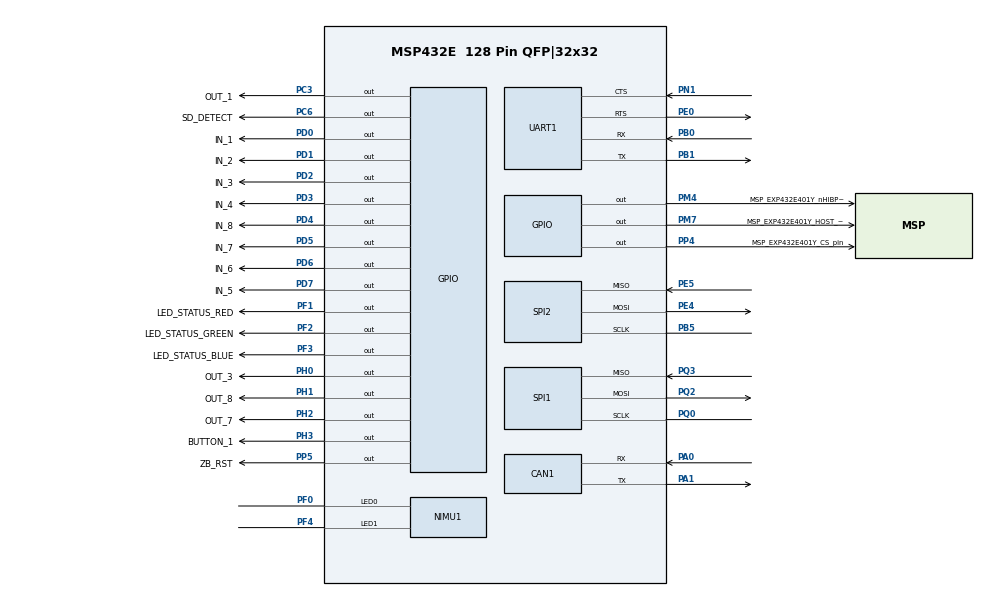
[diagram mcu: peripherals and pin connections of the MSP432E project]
/**
 * @cliArgs --device "MSP432E" --package "128 Pin QFP|32x32" --part "MSP432E401YTPDT" --product "simplelink_msp432e4_sdk@4.20.00.12"
 * @versions {"tool":"1.18.1+3343"}
 */

/**
 * Import the modules used in this configuration.
 */
const CAN     = scripting.addModule("/ti/drivers/CAN", {}, false);
const CAN1    = CAN.addInstance();
const GPIO    = scripting.addModule("/ti/drivers/GPIO", {}, false);
const GPIO1   = GPIO.addInstance();
const GPIO2   = GPIO.addInstance();
const GPIO3   = GPIO.addInstance();
const GPIO4   = GPIO.addInstance();
const GPIO5   = GPIO.addInstance();
const GPIO6   = GPIO.addInstance();
const GPIO7   = GPIO.addInstance();
const GPIO8   = GPIO.addInstance();
const GPIO9   = GPIO.addInstance();
const GPIO10  = GPIO.addInstance();
const GPIO11  = GPIO.addInstance();
const GPIO12  = GPIO.addInstance();
const GPIO13  = GPIO.addInstance();
const GPIO14  = GPIO.addInstance();
const GPIO15  = GPIO.addInstance();
const GPIO16  = GPIO.addInstance();
const GPIO17  = GPIO.addInstance();
const NVS     = scripting.addModule("/ti/drivers/NVS", {}, false);
const NVS1    = NVS.addInstance();
const NVS2    = NVS.addInstance();
const RTOS    = scripting.addModule("/ti/drivers/RTOS");
const SPI     = scripting.addModule("/ti/drivers/SPI", {}, false);
const SPI1    = SPI.addInstance();
const SPI2    = SPI.addInstance();
const Timer   = scripting.addModule("/ti/drivers/Timer", {}, false);
const Timer1  = Timer.addInstance();
const UART    = scripting.addModule("/ti/drivers/UART", {}, false);
const UART1   = UART.addInstance();
const Button  = scripting.addModule("/ti/drivers/apps/Button");
const Button1 = Button.addInstance();
const LED     = scripting.addModule("/ti/drivers/apps/LED");
const LED1    = LED.addInstance();
const LED2    = LED.addInstance();
const LED3    = LED.addInstance();
const General = scripting.addModule("/ti/ndk/General");
const NIMU    = scripting.addModule("/ti/ndk/NIMU", {}, false);
const NIMU1   = NIMU.addInstance();
const SlNet   = scripting.addModule("/ti/net/SlNet", {}, false);
const SlNet1  = SlNet.addInstance();

/**
 * Write custom configuration values to the imported modules.
 */
CAN1.$name             = "CONFIG_CAN0";
CAN1.can.$assign       = "CAN0";
CAN1.can.rxPin.$assign = "PA0";
CAN1.can.txPin.$assign = "PA1";

GPIO1.mode            = "Output";
GPIO1.$name           = "OUT_1";
GPIO1.gpioPin.$assign = "PC3";

GPIO2.mode            = "Output";
GPIO2.$name           = "OUT_3";
GPIO2.gpioPin.$assign = "PH0";

GPIO3.mode            = "Output";
GPIO3.$name           = "OUT_8";
GPIO3.gpioPin.$assign = "PH1";

GPIO4.mode            = "Output";
GPIO4.$name           = "OUT_7";
GPIO4.gpioPin.$assign = "PH2";

GPIO5.callbackFunction = "get_8io";
GPIO5.interruptTrigger = "Both Edges";
GPIO5.pull             = "Pull Up";
GPIO5.$name            = "IN_4";
GPIO5.gpioPin.$assign  = "PD3";

GPIO6.callbackFunction = "get_8io";
GPIO6.interruptTrigger = "Both Edges";
GPIO6.pull             = "Pull Up";
GPIO6.$name            = "IN_3";
GPIO6.gpioPin.$assign  = "PD2";

GPIO7.callbackFunction = "get_8io";
GPIO7.interruptTrigger = "Both Edges";
GPIO7.pull             = "Pull Up";
GPIO7.$name            = "IN_2";
GPIO7.gpioPin.$assign  = "PD1";

GPIO8.callbackFunction = "get_8io";
GPIO8.interruptTrigger = "Both Edges";
GPIO8.pull             = "Pull Up";
GPIO8.$name            = "IN_1";
GPIO8.gpioPin.$assign  = "PD0";

GPIO9.callbackFunction = "get_8io";
GPIO9.interruptTrigger = "Both Edges";
GPIO9.pull             = "Pull Up";
GPIO9.$name            = "IN_8";
GPIO9.gpioPin.$assign  = "PD4";

GPIO10.callbackFunction = "get_8io";
GPIO10.interruptTrigger = "Both Edges";
GPIO10.pull             = "Pull Up";
GPIO10.$name            = "IN_7";
GPIO10.gpioPin.$assign  = "PD5";

GPIO11.callbackFunction = "get_8io";
GPIO11.interruptTrigger = "Both Edges";
GPIO11.pull             = "Pull Up";
GPIO11.$name            = "IN_6";
GPIO11.gpioPin.$assign  = "PD6";

GPIO12.callbackFunction = "get_8io";
GPIO12.interruptTrigger = "Both Edges";
GPIO12.pull             = "Pull Up";
GPIO12.$name            = "IN_5";
GPIO12.gpioPin.$assign  = "PD7";

GPIO13.$name            = "SD_DETECT";
GPIO13.callbackFunction = "sd_pinevent";
GPIO13.interruptTrigger = "Both Edges";
GPIO13.gpioPin.$assign  = "PC6";

GPIO14.$name           = "ZB_RST";
GPIO14.gpioPin.$assign = "PP5";

GPIO15.$name            = "MSP_EXP432E401Y_HOST_IRQ";
GPIO15.pull             = "Pull Down";
GPIO15.interruptTrigger = "Rising Edge";
GPIO15.gpioPin.$assign  = "PM7";

GPIO16.$name           = "MSP_EXP432E401Y_nHIBPin";
GPIO16.mode            = "Output";
GPIO16.outputStrength  = "High";
GPIO16.gpioPin.$assign = "PM4";

GPIO17.$name              = "MSP_EXP432E401Y_CS_pin";
GPIO17.mode               = "Output";
GPIO17.outputStrength     = "High";
GPIO17.initialOutputState = "High";
GPIO17.gpioPin.$assign    = "PP4";

NVS1.$name                    = "CONFIG_NVS_0";
NVS1.internalFlash.$name      = "ti_drivers_nvs_NVSMSP432E40";
NVS1.internalFlash.regionType = "Pointer";
NVS1.internalFlash.regionBase = 0xFC000;

NVS2.nvsType                  = "External";
NVS2.$name                    = "EXTERNAL";
NVS2.externalFlash.$name      = "ti_drivers_nvs_NVSSPI25X0";
NVS2.externalFlash.regionSize = 0x200000;
NVS2.externalFlash.regionBase = 0x20040000;

RTOS.timer0.resource.$assign = "Timer0";

SPI2.$name               = "CONFIG_SPI_WIFI";
SPI2.spi.$assign         = "SSI1";
SPI2.spi.sclkPin.$assign = "PB5";
SPI2.spi.misoPin.$assign = "PE5";
SPI2.spi.mosiPin.$assign = "PE4";

Timer1.$name         = "CONFIG_TIMER_0";
Timer1.timerType     = "32 Bits";
Timer1.timer.$assign = "Timer1";

UART1.$name               = "ZNP_UART";
UART1.flowControl         = true;
UART1.uart.txPin.$assign  = "PB1";
UART1.uart.rxPin.$assign  = "PB0";
UART1.uart.ctsPin.$assign = "PN1";
UART1.uart.rtsPin.$assign = "PE0";

Button1.$name                   = "BUTTON_1";
Button1.gpioPin.$name           = "CONFIG_GPIO_2";
Button1.gpioPin.gpioPin.$assign = "PH3";

LED1.$name                   = "LED_STATUS_RED";
LED1.gpioPin.gpioPin.$assign = "PF1";

LED2.$name                   = "LED_STATUS_BLUE";
LED2.gpioPin.gpioPin.$assign = "PF3";

LED3.$name                   = "LED_STATUS_GREEN";
LED3.gpioPin.gpioPin.$assign = "PF2";

const NVSSPI25XDevice                          = scripting.addModule("/ti/drivers/nvs/NVSSPI25XDevice", {}, false);
const NVSSPI25XDevice1                         = NVSSPI25XDevice.addInstance({}, false);
NVS2.externalFlash.spiFlashDevice              = NVSSPI25XDevice1;
NVSSPI25XDevice1.$name                         = "CONFIG_NVS_SPI_";
NVSSPI25XDevice1.bitRate                       = 12000000;
NVSSPI25XDevice1.slaveSelectGpioInstance.$name = "CONFIG_GPIO_0";

NVSSPI25XDevice1.sharedSpiInstance = SPI1;
SPI1.$name                         = "CONFIG_SPI_FLASH";
SPI1.spi.$assign                   = "SSI3";
SPI1.spi.sclkPin.$assign           = "PQ0";
SPI1.spi.misoPin.$assign           = "PQ3";
SPI1.spi.mosiPin.$assign           = "PQ2";

General.networkIPAddrHook       = "on_ip_change";
General.hostname                = "swaway-rt";
General.enableExtDNS            = true;
General.externDNSServIPAddr     = "9.9.9.9";
General.maxNumSocks             = 20;
General.ndkThreadStkSize        = 4096;
General.netTaskSchedulerTaskPri = "NC_PRIORITY_HIGH";
General.numPBMFrames            = 20;
General.tcpTxBufSize            = 4096;

NIMU1.$name                     = "CONFIG_NIMU_0";
NIMU1.dhcpcServReportFxn        = "on_ip_change";
NIMU1.staticIPAddr              = "192.168.20.98";
NIMU1.gatewayIpAddr             = "192.168.20.1";
NIMU1.localIPAddrConfig         = "Do Not Configure an IP Address";
NIMU1.emac.$name                = "CONFIG_EMAC_0";
NIMU1.emac.emac.$assign         = "ETHERNET0";
NIMU1.emac.emac.led0Pin.$assign = "PF0";
NIMU1.emac.emac.led1Pin.$assign = "PF4";

SlNet1.$name                        = "CONFIG_SLNET_0";
SlNet1.SECOBJ.create(3);
SlNet1.SECOBJ[0].$name              = "CONFIG_SECOBJ_0";
SlNet1.SECOBJ[0].secObjType         = "SLNETIF_SEC_OBJ_TYPE_RSA_PRIVATE_KEY";
SlNet1.SECOBJ[0].secObjVariable     = "sc_sec_pk";
SlNet1.SECOBJ[0].secObjVariableSize = "sc_sec_pk_l";
SlNet1.SECOBJ[1].$name              = "CONFIG_SECOBJ_1";
SlNet1.SECOBJ[1].secObjVariable     = "sc_sec_pc";
SlNet1.SECOBJ[1].secObjVariableSize = "sc_sec_pc_l";
SlNet1.SECOBJ[2].$name              = "CONFIG_SECOBJ_2";
SlNet1.SECOBJ[2].secObjVariable     = "sc_sec_ca";
SlNet1.SECOBJ[2].secObjVariableSize = "sc_sec_ca_l";

/**
 * Pinmux solution for unlocked pins/peripherals. This ensures that minor changes to the automatic solver in a future
 * version of the tool will not impact the pinmux you originally saw.  These lines can be completely deleted in order to
 * re-solve from scratch.
 */
SPI2.spi.dmaRxChannel.$suggestSolution                            = "UDMA_CH10";
SPI2.spi.dmaTxChannel.$suggestSolution                            = "UDMA_CH11";
UART1.uart.$suggestSolution                                       = "UART1";
NVSSPI25XDevice1.slaveSelectGpioInstance.gpioPin.$suggestSolution = "PQ1";
SPI1.spi.dmaRxChannel.$suggestSolution                            = "UDMA_CH14";
SPI1.spi.dmaTxChannel.$suggestSolution                            = "UDMA_CH15";
